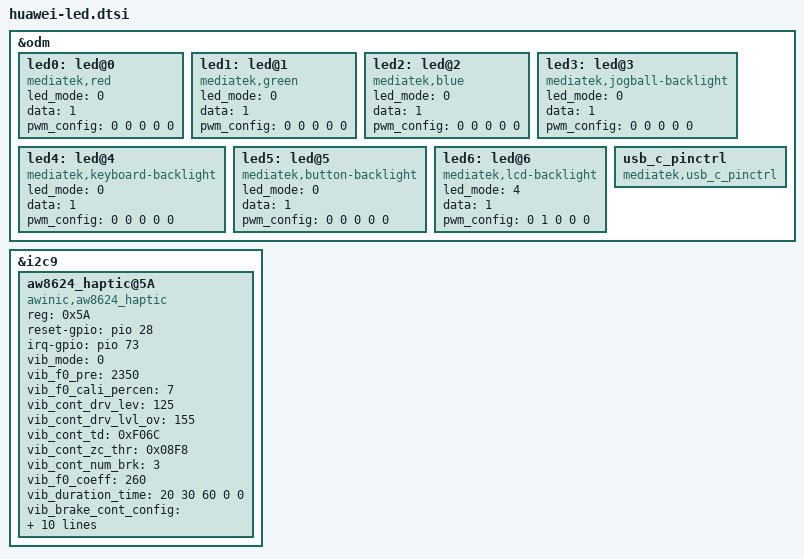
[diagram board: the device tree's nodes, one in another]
&odm {
	led0:led@0 {
		compatible = "mediatek,red";
		led_mode = <0>;
		data = <1>;
		pwm_config = <0 0 0 0 0>;
	};
	led1:led@1 {
		compatible = "mediatek,green";
		led_mode = <0>;
		data = <1>;
		pwm_config = <0 0 0 0 0>;
	};
	led2:led@2 {
		compatible = "mediatek,blue";
		led_mode = <0>;
		data = <1>;
		pwm_config = <0 0 0 0 0>;
	};
	led3:led@3 {
		compatible = "mediatek,jogball-backlight";
		led_mode = <0>;
		data = <1>;
		pwm_config = <0 0 0 0 0>;
	};
	led4:led@4 {
		compatible = "mediatek,keyboard-backlight";
		led_mode = <0>;
		data = <1>;
		pwm_config = <0 0 0 0 0>;
	};
	led5:led@5 {
		compatible = "mediatek,button-backlight";
		led_mode = <0>;
		data = <1>;
		pwm_config = <0 0 0 0 0>;
	};
	led6:led@6 {
		compatible = "mediatek,lcd-backlight";
		led_mode = <4>;
		data = <1>;
		pwm_config = <0 1 0 0 0>;
	};
	usb_c_pinctrl:usb_c_pinctrl {
		compatible = "mediatek,usb_c_pinctrl";
	};
};
&i2c9 {
	aw8624_haptic@5A {
		compatible = "awinic,aw8624_haptic";
		reg = <0x5A>;
		reset-gpio = <&pio 28 0>;
		irq-gpio = <&pio 73 0>;
		vib_mode = < 0 >;  /*mode:  RAM mode->0; CONT mode -> 1*/
		vib_f0_pre = < 2350 >;
		vib_f0_cali_percen = < 7 >;
		vib_cont_drv_lev = < 125 >;
		vib_cont_drv_lvl_ov = < 155 >;
		vib_cont_td = < 0xF06C >;
		vib_cont_zc_thr = < 0x08F8 >;
		vib_cont_num_brk = < 3 >;
		vib_f0_coeff = < 260 >; /*Don't modify it*/
		vib_duration_time = < 20 30 60 0 0 >;
		vib_brake_cont_config = < 1 1 90 42 20 5 2 2 0 0 0  0  0  0 0 0 0 0 0   0  0  0 0 0 >;
		vib_f0_trace_parameter = < 9 5 1 15 >;
		vib_bemf_config = < 0x10 0x08 0x23 0xf8 >;
		vib_sw_brake = < 0x2c 0x08>; /*cont brake,other brake*/
		vib_wavseq = < 1 2 3 4 5 6 7 8 9 10 0 0 0 0 0 0 >; /*wavseq1-seq8 0x07-0x0E*/
		vib_wavloop = < 1 1 1 1 1 1 1 1 1 1>;/*loop1-mainloog 0x0f-0x13*/
		vib_td_brake = < 42720 42720 42720 >; /*level0  level1  level2*/
		vib_tset = < 0x11 >;
		vib_func_parameter1 = < 1 >;
		boost_power_on = < 1 >;
		status = "okay";
	};
};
